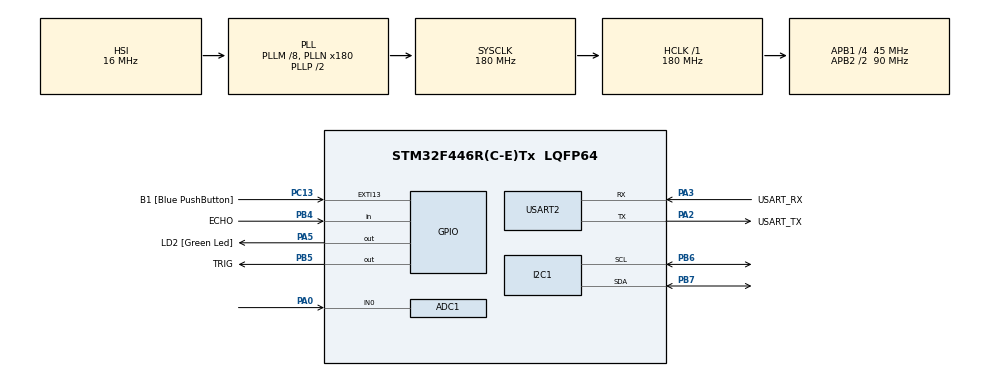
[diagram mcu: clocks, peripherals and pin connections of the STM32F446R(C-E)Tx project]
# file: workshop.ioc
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ADC1.Channel-0\#ChannelRegularConversion=ADC_CHANNEL_0
ADC1.NbrOfConversionFlag=1
ADC1.Rank-0\#ChannelRegularConversion=1
ADC1.SamplingTime-0\#ChannelRegularConversion=ADC_SAMPLETIME_3CYCLES
ADC1.master=1
Mcu.Family=STM32F4
Mcu.Name=STM32F446R(C-E)Tx
Mcu.Package=LQFP64
NVIC.EXTI15_10_IRQn=true\:0\:0\:false\:false\:true\:true\:true\:true
NVIC.PriorityGroup=NVIC_PRIORITYGROUP_0
PA0-WKUP.Signal=ADCx_IN0
PA13.GPIO_Label=TMS
PA13.Mode=Serial_Wire
PA13.Signal=SYS_JTMS-SWDIO
PA14.GPIO_Label=TCK
PA14.Mode=Serial_Wire
PA14.Signal=SYS_JTCK-SWCLK
PA2.GPIO_Label=USART_TX
PA2.Mode=Asynchronous
PA2.Signal=USART2_TX
PA3.GPIO_Label=USART_RX
PA3.Mode=Asynchronous
PA3.Signal=USART2_RX
PA5.GPIO_Label=LD2 [Green Led]
PA5.Signal=GPIO_Output
PB3.GPIO_Label=SWO
PB3.Signal=SYS_JTDO-SWO
PB4.GPIO_Label=ECHO
PB4.Signal=GPIO_Input
PB5.GPIO_Label=TRIG
PB5.Signal=GPIO_Output
PB6.Mode=I2C
PB6.Signal=I2C1_SCL
PB7.Mode=I2C
PB7.Signal=I2C1_SDA
PC13.GPIO_Label=B1 [Blue PushButton]
PC13.GPIO_ModeDefaultEXTI=GPIO_MODE_IT_FALLING
PC13.Signal=GPXTI13
PC14-OSC32_IN.Mode=LSE-External-Oscillator
PC14-OSC32_IN.Signal=RCC_OSC32_IN
PC15-OSC32_OUT.Mode=LSE-External-Oscillator
PC15-OSC32_OUT.Signal=RCC_OSC32_OUT
PH0-OSC_IN.Mode=HSE-External-Oscillator
PH0-OSC_IN.Signal=RCC_OSC_IN
PH1-OSC_OUT.Mode=HSE-External-Oscillator
PH1-OSC_OUT.Signal=RCC_OSC_OUT
ProjectManager.HeapSize=0x200
ProjectManager.StackSize=0x400
ProjectManager.TargetToolchain=STM32CubeIDE
RCC.48MHZClocksFreq_Value=84000000
RCC.AHBFreq_Value=180000000
RCC.APB1CLKDivider=RCC_HCLK_DIV4
RCC.APB1Freq_Value=45000000
RCC.APB1TimFreq_Value=90000000
RCC.APB2CLKDivider=RCC_HCLK_DIV2
RCC.APB2Freq_Value=90000000
RCC.APB2TimFreq_Value=180000000
RCC.CortexFreq_Value=180000000
RCC.FLatency-AdvancedSettings=FLASH_LATENCY_5
RCC.HCLKFreq_Value=180000000
RCC.HSE_VALUE=8000000
RCC.HSI_VALUE=16000000
RCC.PLLM=8
RCC.PLLN=180
RCC.SYSCLKFreq_VALUE=180000000
RCC.SYSCLKSource=RCC_SYSCLKSOURCE_PLLCLK
RCC.USBFreq_Value=180000000
RCC.VCOOutputFreq_Value=360000000
SH.ADCx_IN0.0=ADC1_IN0,IN0
TIM2.Period=4294967295
TIM2.Prescaler=89
USART2.VirtualMode=VM_ASYNC
VP_TIM2_VS_ClockSourceINT.Mode=Internal
board=NUCLEO-F446RE

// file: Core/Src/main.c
/* USER CODE BEGIN Header */
/**
  ******************************************************************************
  * @file           : main.c
  * @brief          : Main program body
  ******************************************************************************
  * @attention
  *
  * Copyright (c) 2026 STMicroelectronics.
  * All rights reserved.
  *
  * This software is licensed under terms that can be found in the LICENSE file
  * in the root directory of this software component.
  * If no LICENSE file comes with this software, it is provided AS-IS.
  *
  ******************************************************************************
  */
/* USER CODE END Header */
#include "main.h"
#include "sensor_display.h"

ADC_HandleTypeDef hadc1;

I2C_HandleTypeDef hi2c1;

TIM_HandleTypeDef htim2;

UART_HandleTypeDef huart2;

/* USER CODE BEGIN PV */
uint8_t B1_EVTFlag;

/* USER CODE END PV */

void SystemClock_Config(void);
static void MX_GPIO_Init(void);
static void MX_ADC1_Init(void);
static void MX_USART2_UART_Init(void);
static void MX_TIM2_Init(void);
static void MX_I2C1_Init(void);

int main(void)
{

  /* MCU Configuration--------------------------------------------------------*/

  /* Reset of all peripherals, Initializes the Flash interface and the Systick. */
  HAL_Init();

  /* Configure the system clock */
  SystemClock_Config();

  /* Initialize all configured peripherals */
  MX_GPIO_Init();
  MX_ADC1_Init();
  MX_USART2_UART_Init();
  MX_TIM2_Init();
  MX_I2C1_Init();
  /* USER CODE BEGIN 2 */

  HAL_TIM_Base_Start(&htim2);
  HAL_Delay(500);
  SensorDisplay_Init();
  /* USER CODE END 2 */

  /* Infinite loop */
  /* USER CODE BEGIN WHILE */

  /* USER CODE BEGIN WHILE */
  while (1)
  {
	    SensorDisplay_Update();
	    HAL_Delay(300);
    /* USER CODE END WHILE */

  }
}

void SystemClock_Config(void)
{
  RCC_OscInitTypeDef RCC_OscInitStruct = {0};
  RCC_ClkInitTypeDef RCC_ClkInitStruct = {0};

  /** Configure the main internal regulator output voltage
  */
  __HAL_RCC_PWR_CLK_ENABLE();
  __HAL_PWR_VOLTAGESCALING_CONFIG(PWR_REGULATOR_VOLTAGE_SCALE1);

  /** Initializes the RCC Oscillators according to the specified parameters
  * in the RCC_OscInitTypeDef structure.
  */
  RCC_OscInitStruct.OscillatorType = RCC_OSCILLATORTYPE_HSI;
  RCC_OscInitStruct.HSIState = RCC_HSI_ON;
  RCC_OscInitStruct.HSICalibrationValue = RCC_HSICALIBRATION_DEFAULT;
  RCC_OscInitStruct.PLL.PLLState = RCC_PLL_ON;
  RCC_OscInitStruct.PLL.PLLSource = RCC_PLLSOURCE_HSI;
  RCC_OscInitStruct.PLL.PLLM = 8;
  RCC_OscInitStruct.PLL.PLLN = 180;
  RCC_OscInitStruct.PLL.PLLP = RCC_PLLP_DIV2;
  RCC_OscInitStruct.PLL.PLLQ = 2;
  RCC_OscInitStruct.PLL.PLLR = 2;
  if (HAL_RCC_OscConfig(&RCC_OscInitStruct) != HAL_OK)
  {
    Error_Handler();
  }

  /** Activate the Over-Drive mode
  */
  if (HAL_PWREx_EnableOverDrive() != HAL_OK)
  {
    Error_Handler();
  }

  /** Initializes the CPU, AHB and APB buses clocks
  */
  RCC_ClkInitStruct.ClockType = RCC_CLOCKTYPE_HCLK|RCC_CLOCKTYPE_SYSCLK
                              |RCC_CLOCKTYPE_PCLK1|RCC_CLOCKTYPE_PCLK2;
  RCC_ClkInitStruct.SYSCLKSource = RCC_SYSCLKSOURCE_PLLCLK;
  RCC_ClkInitStruct.AHBCLKDivider = RCC_SYSCLK_DIV1;
  RCC_ClkInitStruct.APB1CLKDivider = RCC_HCLK_DIV4;
  RCC_ClkInitStruct.APB2CLKDivider = RCC_HCLK_DIV2;

  if (HAL_RCC_ClockConfig(&RCC_ClkInitStruct, FLASH_LATENCY_5) != HAL_OK)
  {
    Error_Handler();
  }
}

static void MX_ADC1_Init(void)
{

  ADC_ChannelConfTypeDef sConfig = {0};

  /** Configure the global features of the ADC (Clock, Resolution, Data Alignment and number of conversion)
  */
  hadc1.Instance = ADC1;
  hadc1.Init.ClockPrescaler = ADC_CLOCK_SYNC_PCLK_DIV4;
  hadc1.Init.Resolution = ADC_RESOLUTION_12B;
  hadc1.Init.ScanConvMode = DISABLE;
  hadc1.Init.ContinuousConvMode = DISABLE;
  hadc1.Init.DiscontinuousConvMode = DISABLE;
  hadc1.Init.ExternalTrigConvEdge = ADC_EXTERNALTRIGCONVEDGE_NONE;
  hadc1.Init.ExternalTrigConv = ADC_SOFTWARE_START;
  hadc1.Init.DataAlign = ADC_DATAALIGN_RIGHT;
  hadc1.Init.NbrOfConversion = 1;
  hadc1.Init.DMAContinuousRequests = DISABLE;
  hadc1.Init.EOCSelection = ADC_EOC_SINGLE_CONV;
  if (HAL_ADC_Init(&hadc1) != HAL_OK)
  {
    Error_Handler();
  }

  /** Configure for the selected ADC regular channel its corresponding rank in the sequencer and its sample time.
  */
  sConfig.Channel = ADC_CHANNEL_0;
  sConfig.Rank = 1;
  sConfig.SamplingTime = ADC_SAMPLETIME_3CYCLES;
  if (HAL_ADC_ConfigChannel(&hadc1, &sConfig) != HAL_OK)
  {
    Error_Handler();
  }

}

static void MX_I2C1_Init(void)
{

  hi2c1.Instance = I2C1;
  hi2c1.Init.ClockSpeed = 100000;
  hi2c1.Init.DutyCycle = I2C_DUTYCYCLE_2;
  hi2c1.Init.OwnAddress1 = 0;
  hi2c1.Init.AddressingMode = I2C_ADDRESSINGMODE_7BIT;
  hi2c1.Init.DualAddressMode = I2C_DUALADDRESS_DISABLE;
  hi2c1.Init.OwnAddress2 = 0;
  hi2c1.Init.GeneralCallMode = I2C_GENERALCALL_DISABLE;
  hi2c1.Init.NoStretchMode = I2C_NOSTRETCH_DISABLE;
  if (HAL_I2C_Init(&hi2c1) != HAL_OK)
  {
    Error_Handler();
  }

}

static void MX_TIM2_Init(void)
{

  TIM_ClockConfigTypeDef sClockSourceConfig = {0};
  TIM_MasterConfigTypeDef sMasterConfig = {0};

  htim2.Instance = TIM2;
  htim2.Init.Prescaler = 89;
  htim2.Init.CounterMode = TIM_COUNTERMODE_UP;
  htim2.Init.Period = 4294967295;
  htim2.Init.ClockDivision = TIM_CLOCKDIVISION_DIV1;
  htim2.Init.AutoReloadPreload = TIM_AUTORELOAD_PRELOAD_DISABLE;
  if (HAL_TIM_Base_Init(&htim2) != HAL_OK)
  {
    Error_Handler();
  }
  sClockSourceConfig.ClockSource = TIM_CLOCKSOURCE_INTERNAL;
  if (HAL_TIM_ConfigClockSource(&htim2, &sClockSourceConfig) != HAL_OK)
  {
    Error_Handler();
  }
  sMasterConfig.MasterOutputTrigger = TIM_TRGO_RESET;
  sMasterConfig.MasterSlaveMode = TIM_MASTERSLAVEMODE_DISABLE;
  if (HAL_TIMEx_MasterConfigSynchronization(&htim2, &sMasterConfig) != HAL_OK)
  {
    Error_Handler();
  }

}

static void MX_USART2_UART_Init(void)
{

  huart2.Instance = USART2;
  huart2.Init.BaudRate = 115200;
  huart2.Init.WordLength = UART_WORDLENGTH_8B;
  huart2.Init.StopBits = UART_STOPBITS_1;
  huart2.Init.Parity = UART_PARITY_NONE;
  huart2.Init.Mode = UART_MODE_TX_RX;
  huart2.Init.HwFlowCtl = UART_HWCONTROL_NONE;
  huart2.Init.OverSampling = UART_OVERSAMPLING_16;
  if (HAL_UART_Init(&huart2) != HAL_OK)
  {
    Error_Handler();
  }

}

static void MX_GPIO_Init(void)
{
  GPIO_InitTypeDef GPIO_InitStruct = {0};

  /* GPIO Ports Clock Enable */
  __HAL_RCC_GPIOC_CLK_ENABLE();
  __HAL_RCC_GPIOH_CLK_ENABLE();
  __HAL_RCC_GPIOA_CLK_ENABLE();
  __HAL_RCC_GPIOB_CLK_ENABLE();

  /*Configure GPIO pin Output Level */
  HAL_GPIO_WritePin(LD2_GPIO_Port, LD2_Pin, GPIO_PIN_RESET);

  /*Configure GPIO pin Output Level */
  HAL_GPIO_WritePin(TRIG_GPIO_Port, TRIG_Pin, GPIO_PIN_RESET);

  /*Configure GPIO pin : B1_Pin */
  GPIO_InitStruct.Pin = B1_Pin;
  GPIO_InitStruct.Mode = GPIO_MODE_IT_FALLING;
  GPIO_InitStruct.Pull = GPIO_NOPULL;
  HAL_GPIO_Init(B1_GPIO_Port, &GPIO_InitStruct);

  /*Configure GPIO pin : LD2_Pin */
  GPIO_InitStruct.Pin = LD2_Pin;
  GPIO_InitStruct.Mode = GPIO_MODE_OUTPUT_PP;
  GPIO_InitStruct.Pull = GPIO_NOPULL;
  GPIO_InitStruct.Speed = GPIO_SPEED_FREQ_LOW;
  HAL_GPIO_Init(LD2_GPIO_Port, &GPIO_InitStruct);

  /*Configure GPIO pin : ECHO_Pin */
  GPIO_InitStruct.Pin = ECHO_Pin;
  GPIO_InitStruct.Mode = GPIO_MODE_INPUT;
  GPIO_InitStruct.Pull = GPIO_NOPULL;
  HAL_GPIO_Init(ECHO_GPIO_Port, &GPIO_InitStruct);

  /*Configure GPIO pin : TRIG_Pin */
  GPIO_InitStruct.Pin = TRIG_Pin;
  GPIO_InitStruct.Mode = GPIO_MODE_OUTPUT_PP;
  GPIO_InitStruct.Pull = GPIO_NOPULL;
  GPIO_InitStruct.Speed = GPIO_SPEED_FREQ_LOW;
  HAL_GPIO_Init(TRIG_GPIO_Port, &GPIO_InitStruct);

  /* EXTI interrupt init*/
  HAL_NVIC_SetPriority(EXTI15_10_IRQn, 0, 0);
  HAL_NVIC_EnableIRQ(EXTI15_10_IRQn);

}

/* USER CODE BEGIN 4 */
void HAL_GPIO_EXTI_Callback(uint16_t GPIO_Pin)
{

	if(GPIO_Pin == B1_Pin){
		B1_EVTFlag = 1;
	}
  /* Prevent unused argument(s) compilation warning */
  /* NOTE: This function Should not be modified, when the callback is needed,
           the HAL_GPIO_EXTI_Callback could be implemented in the user file
   */
}

/* USER CODE END 4 */

void Error_Handler(void)
{
  __disable_irq();
  while (1)
  {
  }
}
